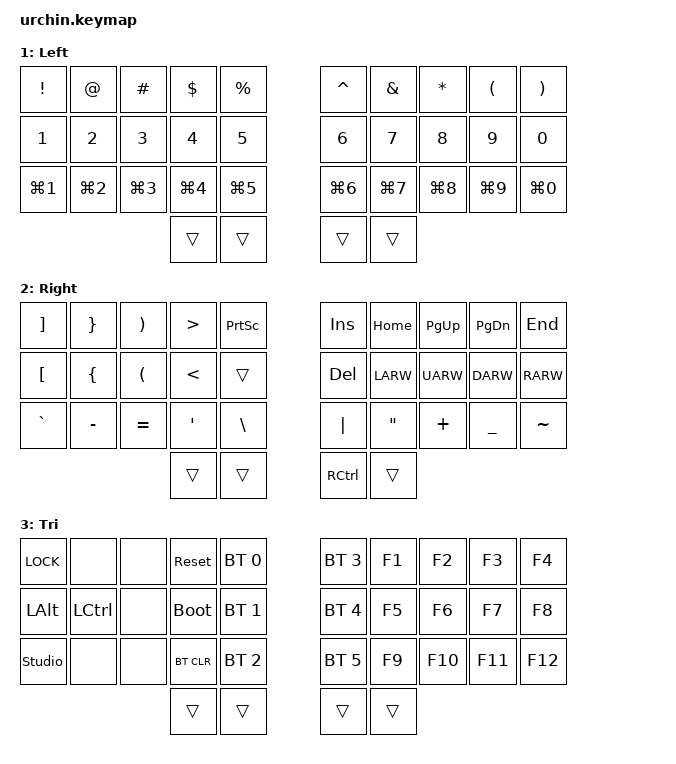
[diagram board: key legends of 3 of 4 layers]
// Copyright (c) 2025 Felipe Balbi
// SPDX-License-Identifier: MIT

#include <behaviors.dtsi>
#include <dt-bindings/zmk/keys.h>
#include <dt-bindings/zmk/bt.h>
#include <dt-bindings/zmk/outputs.h>

// Home row mods macro
#define HRML(k1,k2,k3,k4)	&hml LSHFT k1 &hml LALT k2 &hml LGUI k3 &hml LCTRL k4
#define HRMR(k1,k2,k3,k4)	&hmr RCTRL k1 &hmr RGUI k2 &hmr RALT k3 &hmr RSHFT k4

// Custom lock keychord
#define LOCK LG(LC(L))

#define BSE	0
#define LEF	1
#define RIG	2
#define TRI	3

/ {
	behaviors {
		hml: homerow_mods_left {
			compatible = "zmk,behavior-hold-tap";
			label = "homerow_mods_left";
			#binding-cells = <2>;
			flavor = "balanced";
			tapping-term-ms = <200>;
			quick-tap-ms = <0>;
			/* global-quick-tap; */
			bindings = <&kp>, <&kp>;
			hold-trigger-key-positions = <
				 5  6  7  8  9
				15 16 17 18 19
				25 26 27 28 29
				32 33
			>;
			hold-trigger-on-release;
		};

		hmr: homerow_mods_right {
			compatible = "zmk,behavior-hold-tap";
			label = "homerow_mods_right";
			#binding-cells = <2>;
			flavor = "balanced";
			tapping-term-ms = <200>;
			quick-tap-ms = <0>;
			/* global-quick-tap; */
			bindings = <&kp>, <&kp>;
			hold-trigger-key-positions = <
				 0  1  2  3  4
				10 11 12 13 14
				20 21 22 23 24
				         30 31
			>;
			hold-trigger-on-release;
		};
	};

	macros {
		// sometimes my device thinks a modifier is being held down
		// pressing all modifiers fixes it.
		unstick: unstick {
			label = "ZM_unstick";
			compatible = "zmk,behavior-macro";
			#binding-cells = <0>;
			bindings = <&kp LSHIFT &kp RSHIFT &kp LCTRL &kp RCTRL &kp LALT &kp RALT &kp LGUI &kp RGUI>;
		};
	};

	combos {
		compatible = "zmk,combos";

		// Both left thumb keys
		combo_esc {
			timeout-ms = <50>;
			key-positions = <30 31>;
			bindings = <&kp ESC>;
		};

		// Both right thumb keys
		combo_delete {
			timeout-ms = <50>;
			key-positions = <32 33>;
			bindings = <&kp DEL>;
		};

		// External left and right thumb keys
		combo_caps_word {
			timeout-ms = <50>;
			key-positions = <31 32>;
			bindings = <&caps_word>;
		};
	};

	conditional_layers {
		compatible = "zmk,conditional-layers";
		tri_layer {
			if-layers = <LEF RIG>;
			then-layer = <TRI>;
		};
	};

	keymap {
		compatible = "zmk,keymap";
		alpha_layer {
			label = "Alpha";
			bindings = <
			//╭──────────┬──────────┬──────────┬──────────┬──────────╮   ╭──────────┬──────────┬──────────┬──────────┬──────────╮
			//│  Q	     │	W	│  E	   │  R	      │	 T	 │   │	Y	│  U	   │  I	      │	 O	 │  P	    │
			   &kp Q      &kp W	  &kp E	     &kp R	&kp T	       &kp Y	  &kp U	     &kp I	&kp O	   &kp P
			//├──────────┼──────────┼──────────┼──────────┼──────────┤   ├──────────┼──────────┼──────────┼──────────┼──────────┤
			//│  A	     │	S	│  D	   │  F	      │	 G	 │   │	H	│  J	   │  K	      │	 L	 │  ; :	    │
			   HRML(A,	   S,	      D,	 F)	&kp G	       &kp H	  HRMR(J,	 K,	    L,	      SEMI)
			//├──────────┼──────────┼──────────┼──────────┼──────────┤   ├──────────┼──────────┼──────────┼──────────┼──────────┤
			//│  Z	     │	X	│  C	   │  V	      │	 B	 │   │	N	│  M	   │ , <      │ . >	 │ / ?	    │
			   &kp Z      &kp X	  &kp C	     &kp V	&kp B	       &kp N	  &kp M	     &kp COMMA	&kp DOT	   &kp FSLH
			//╰──────────┴──────────┴──────────┼──────────┼──────────┤   ├──────────┼──────────┼──────────┴──────────┴──────────╯
			                                    &lt LEF TAB	&kp ENTER     &kp SPACE	 &lt RIG BSPC
			//				   ╰──────────┴──────────╯   ╰──────────┴──────────╯
			>;
		};

		left_layer {
			label = "Left";
			bindings = <
			//╭──────────┬──────────┬──────────┬──────────┬──────────╮   ╭──────────┬──────────┬──────────┬──────────┬──────────╮
			//│  !	     │	@	│  #	   │  $	      │	 %	 │   │	^	│  &	   │  *	      │	 (	 │  )	    │
			   &kp EXCL   &kp AT	  &kp HASH   &kp DLLR	&kp PRCNT      &kp CARET  &kp AMPS   &kp ASTRK	&kp LPRN   &kp RPRN
			//├──────────┼──────────┼──────────┼──────────┼──────────┤   ├──────────┼──────────┼──────────┼──────────┼──────────┤
			//│  1	     │	2	│  3	   │  4	      │	 5	 │   │	6	│  7	   │  8	      │	 9	 │  0	    │
			   &kp N1     &kp N2	  &kp N3     &kp N4	&kp N5	       &kp N6	  &kp N7     &kp N8	&kp N9	   &kp N0
			//├──────────┼──────────┼──────────┼──────────┼──────────┤   ├──────────┼──────────┼──────────┼──────────┼──────────┤
			//│  GUI(1)  │	GUI(2)	│  GUI(3)  │  GUI(4)  │	 GUI(5)	 │   │	GUI(6)	│  GUI(7)  │  GUI(8)  │	 GUI(9)	 │  GUI(0)  │
			   &kp LG(N1) &kp LG(N2) &kp LG(N3) &kp LG(N4) &kp LG(N5)     &kp LG(N6) &kp LG(N7) &kp LG(N8) &kp LG(N9) &kp LG(N0)
			//╰──────────┴──────────┴──────────┼──────────┼──────────┤   ├──────────┼──────────┼──────────┴──────────┴──────────╯
							     &trans	&trans	       &trans	  &trans
			//				   ╰──────────┴──────────╯   ╰──────────┴──────────╯
			>;
		};

		right_layer {
			label = "Right";
			bindings = <
			//╭──────────┬──────────┬──────────┬──────────┬──────────╮   ╭──────────┬──────────┬──────────┬──────────┬──────────╮
			//│  ]	     │	}	│  )	   │  >	      │ Pr Scrn	 │   │ INSERT	│ HOME	   │ PAGE UP  │ PAGE DN	 │  END	    │
			   &kp RBKT   &kp RBRC	  &kp RPAR   &kp GT	&kp PSCRN      &kp INS	  &kp HOME   &kp PG_UP	&kp PG_DN  &kp END
			//├──────────┼──────────┼──────────┼──────────┼──────────┤   ├──────────┼──────────┼──────────┼──────────┼──────────┤
			//│  [	     │	{	│  (	   │  <	      │		 │   │ DELETE	│ LEFT	   │ UP	      │ DOWN	 │  RIGHT   │
			   &kp LBKT   &kp LBRC	  &kp LPAR   &kp LT	&trans	       &kp DEL	  &kp LARW   &kp UARW	&kp DARW   &kp RARW
			//├──────────┼──────────┼──────────┼──────────┼──────────┤   ├──────────┼──────────┼──────────┼──────────┼──────────┤
			//│  `	     │	-	│  =	   │  '	      │	 \	 │   │	|	│  "	   │  +	      │	 _	 │  ~	    │
			   &kp GRAVE  &kp MINUS  &kp EQUAL  &kp SQT	&kp BSLH       &kp PIPE	 &kp DQT     &kp PLUS	&kp UNDER  &kp TILDE
			//╰──────────┴──────────┴──────────┼──────────┼──────────┤   ├──────────┼──────────┼──────────┴──────────┴──────────╯
							    &trans	&trans	       &kp RCTRL  &trans
			//				   ╰──────────┴──────────╯   ╰──────────┴──────────╯
			>;
		};

		tri_layer {
			label = "Tri";
			bindings = <
			//╭──────────┬──────────┬──────────┬──────────┬──────────╮   ╭──────────┬──────────┬──────────┬──────────┬──────────╮
			//│  LOCK    │		│	   │  RESET   │PROFILE 0 │   │PROFILE 3	│  F1	   │  F2      │	 F3	 │  F4	    │
			   &kp LOCK   &none	  &none   &sys_reset &bt BT_SEL 0   &bt BT_SEL 3  &kp F1     &kp F2	&kp F3	   &kp F4
			//├──────────┼──────────┼──────────┼──────────┼──────────┤   ├──────────┼──────────┼──────────┼──────────┼──────────┤
			//│  ALT     │	CTRL	│	   │BOOTLOADER│PROFILE 1 │   │PROFILE 4	│  F5	   │  F6      │	 F7	 │  F8	    │
			   &kp LALT   &kp LCTRL  &none    &bootloader &bt BT_SEL 1  &bt BT_SEL 4  &kp F5     &kp F6	&kp F7	   &kp F8
			//├──────────┼──────────┼──────────┼──────────┼──────────┤   ├──────────┼──────────┼──────────┼──────────┼──────────┤
			//│	     │		│	   │ CLEAR BT │PROFILE 2 │   │PROFILE 5	│  F9	   │  F10     │	 F11	 │  F12	    │
			&studio_unlock	&none	  &none    &bt BT_CLR &bt BT_SEL 2  &bt BT_SEL 5  &kp F9     &kp F10	&kp F11	   &kp F12
			//╰──────────┴──────────┴──────────┼──────────┼──────────┤   ├──────────┼──────────┼──────────┴──────────┴──────────╯
							    &trans	&trans	       &trans	  &trans
			//				   ╰──────────┴──────────╯   ╰──────────┴──────────╯
			>;
		};
	};
};
